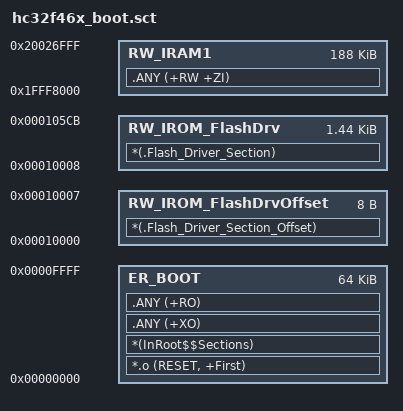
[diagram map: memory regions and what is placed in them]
; *************************************************************
; *** Scatter-Loading Description File generated by uVision ***
; *************************************************************
LR_IROM1 0x00000000 0x00010000  {    ; Total Flash 512K
  ; Bootloader Section
  ER_BOOT 0x00000000 0x00010000  {  ; 64K Bootloader
    *.o (RESET, +First)
    *(InRoot$$Sections)
    .ANY (+XO)
    .ANY (+RO)
  }

  ; RAM Section
  RW_IRAM1 0x1FFF8000 0x0002F000  {  ; RW data
   .ANY (+RW +ZI)
  }
}

LR_IROM2  0x00010000  0x00010000		; 定义加载空间地址和大小，对应工程设置的IROM3。LR_IROM3是加载空间的名称
{
	RW_IROM_FlashDrvOffset  0x00010000 0x00000008
	{
    	*(.Flash_Driver_Section_Offset)    
  
	}
	
	RW_IROM_FlashDrv  0x00010008 0x000005C4
	{										
   		 *(.Flash_Driver_Section)    
	}
}

;LR_IROM2 0x00010000 0x00010000  {    ; Total Flash 512K
;    ER_FLASH 0x00010000 0x00010000  {  ; 64K Flash
;    *.o (FLASH_DRV)
;    * (.NVM_Driver_Section)   
;  }
;}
